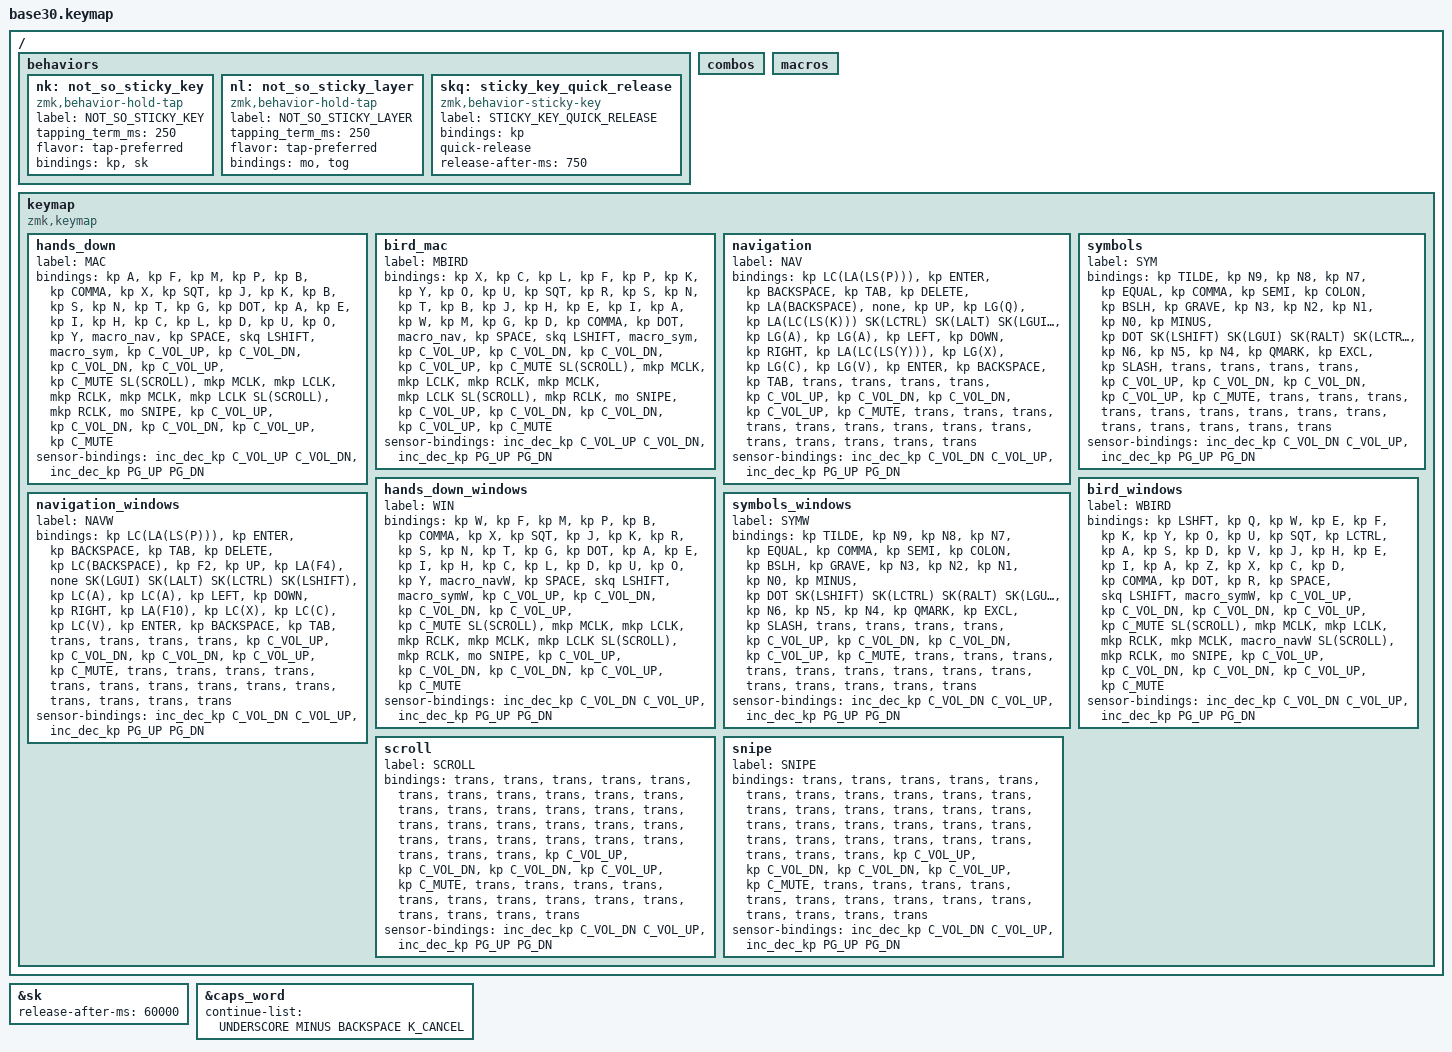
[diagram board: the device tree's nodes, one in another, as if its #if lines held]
/*
 * Copyright (c) 2020 The ZMK Contributors
 *
 * SPDX-License-Identifier: MIT
 */

#include <behaviors.dtsi>
#include <dt-bindings/zmk/keys.h>
#include <dt-bindings/zmk/bt.h>
#include <dt-bindings/zmk/outputs.h>

#define MAC 0
#define MBIRD 1
#define NAV 2
#define SYM 3
#define WIN 4
#define WBIRD 5
#define NAVW 6
#define SYMW 7
#ifdef GHAZAL
  #define SCROLL 8
  #define SNIPE 9
#endif

#define SK(KEY) &nk KEY KEY

#ifdef GHAZAL
  #define SL(LAYER) &nl LAYER LAYER
#endif

&sk {
  release-after-ms = <60000>;
};

&caps_word {
  continue-list = <UNDERSCORE MINUS BACKSPACE K_CANCEL>;
};


/*                KEY POSITIONS

  ╭────────────────────╮ ╭────────────────────╮
  │  0   1   2   3   4 │ │  5   6   7   8   9 │
  │ 10  11  12  13  14 │ │ 15  16  17  18  19 │
  │     20  21  22     │ │     23  24  25     │
  ╰───────────╮ 26  27 │ │ 28  29 ╭───────────╯
              ╰────────╯ ╰────────╯            */

/ {

  behaviors {

    // Sticky key on tap, normal key on hold
    // Useful for modifier-clicking without the modifier remaining active
    nk: not_so_sticky_key {
        compatible = "zmk,behavior-hold-tap";
        label = "NOT_SO_STICKY_KEY";
        #binding-cells = <2>;
        tapping_term_ms = <250>;
        flavor = "tap-preferred";
        bindings = <&kp>, <&sk>;
    };

#ifdef GHAZAL
    // Toggle layer on tap, normal layer on hold
    // Useful for scroll toggling without the scroll remaining active unless held
    nl: not_so_sticky_layer {
        compatible = "zmk,behavior-hold-tap";
        label = "NOT_SO_STICKY_LAYER";
        #binding-cells = <2>;
        tapping_term_ms = <250>;
        flavor = "tap-preferred";
        bindings = <&mo>, <&tog>;
    };
#endif

    skq: sticky_key_quick_release {
      compatible = "zmk,behavior-sticky-key";
      label = "STICKY_KEY_QUICK_RELEASE";
      #binding-cells = <1>;
      bindings = <&kp>;
      quick-release;
      release-after-ms = <750>;
    };

  };

  combos {
        #include "combos30.dtsi"
    };
  macros {
        #include "macros.dtsi"
#include <dt-bindings/zmk/mouse.h>
    };

 
        keymap {
                compatible = "zmk,keymap";
 
        hands_down {
            label = "MAC";
            bindings = <
// ╭─────────────┬─────────────┬─────────────┬─────────────┬─────────────╮   ╭─────────────┬─────────────┬─────────────┬─────────────┬─────────────╮
     &kp A         &kp F         &kp M         &kp P         &kp B             &kp COMMA     &kp X         &kp SQT       &kp J         &kp K
     &kp B         &kp S         &kp N         &kp T         &kp G             &kp DOT       &kp A         &kp E         &kp I         &kp H
                   &kp C         &kp L         &kp D                                         &kp U         &kp O         &kp Y
//               ╰─────────────┴─────────────┼─────────────┤                               ├─────────────┼─────────────┴─────────────╯
                                               &macro_nav   &kp SPACE          &skq LSHIFT    &macro_sym
//                                           ╰─────────────┴─────────────╯   ╰─────────────┴─────────────╯

            #ifdef WASFOORA
                  // up          left         down         right        middle
                   &kp C_VOL_UP  &kp C_VOL_DN &kp C_VOL_DN &kp C_VOL_UP &kp C_MUTE
            #endif

            #ifdef GHAZAL
              SL(SCROLL) 
              &mkp MCLK &mkp LCLK &mkp RCLK
              &mkp MCLK &mkp LCLK SL(SCROLL) &mkp RCLK &mo SNIPE    &kp C_VOL_UP  &kp C_VOL_DN &kp C_VOL_DN &kp C_VOL_UP &kp C_MUTE
            #endif

            >;
            #ifdef ENCODERS
              sensor-bindings = <&inc_dec_kp C_VOL_UP C_VOL_DN &inc_dec_kp PG_UP PG_DN>;
            #endif
        };

        bird_mac {
            label = "MBIRD";
            bindings = <
// ╭─────────────┬─────────────┬─────────────┬─────────────┬─────────────╮   ╭─────────────┬─────────────┬─────────────┬─────────────┬─────────────╮
     &kp X         &kp C         &kp L         &kp F         &kp P             &kp K         &kp Y         &kp O         &kp U         &kp SQT
     &kp R         &kp S         &kp N         &kp T         &kp B             &kp J         &kp H         &kp E         &kp I         &kp A
                   &kp W         &kp M         &kp G                                         &kp D         &kp COMMA     &kp DOT
//               ╰─────────────┴─────────────┼─────────────┤                               ├─────────────┼─────────────┴─────────────╯
                                               &macro_nav   &kp SPACE          &skq LSHIFT    &macro_sym
//                                           ╰─────────────┴─────────────╯   ╰─────────────┴─────────────╯

            #ifdef WASFOORA
                  // up          left         down         right        middle
                   &kp C_VOL_UP  &kp C_VOL_DN &kp C_VOL_DN &kp C_VOL_UP &kp C_MUTE
            #endif

            #ifdef GHAZAL
              SL(SCROLL) 
              &mkp MCLK &mkp LCLK &mkp RCLK
              &mkp MCLK &mkp LCLK SL(SCROLL) &mkp RCLK &mo SNIPE    &kp C_VOL_UP  &kp C_VOL_DN &kp C_VOL_DN &kp C_VOL_UP &kp C_MUTE
            #endif

            >;
            #ifdef ENCODERS
              sensor-bindings = <&inc_dec_kp C_VOL_UP C_VOL_DN &inc_dec_kp PG_UP PG_DN>;
            #endif
        };

        navigation {
            label = "NAV";
            bindings = <
// ╭─────────────┬─────────────┬─────────────┬─────────────┬─────────────╮   ╭─────────────┬─────────────┬─────────────┬─────────────┬─────────────╮
  &kp LC(LA(LS(P)))    &kp ENTER     &kp BACKSPACE  &kp TAB     &kp DELETE      &kp LA(BACKSPACE) &none         &kp UP        &kp LG(Q)  &kp LA(LC(LS(K)))
     SK(LCTRL)         SK(LALT)      SK(LGUI)       SK(LSHIFT)  &kp LG(A)       &kp LG(A)         &kp LEFT      &kp DOWN      &kp RIGHT  &kp LA(LC(LS(Y)))
                       &kp LG(X)     &kp LG(C)      &kp LG(V)                                     &kp ENTER     &kp BACKSPACE &kp TAB
//               ╰─────────────┴─────────────┼─────────────┤                               ├─────────────┼─────────────┴─────────────╯
                                                &trans        &trans            &trans       &trans
//                                           ╰─────────────┴─────────────╯   ╰─────────────┴─────────────╯

            #ifdef WASFOORA
                  // up          left         down         right        middle
                   &kp C_VOL_UP  &kp C_VOL_DN &kp C_VOL_DN &kp C_VOL_UP &kp C_MUTE
            #endif

            #ifdef GHAZAL
              &trans 
              &trans &trans &trans
              &trans &trans &trans &trans &trans       &trans &trans &trans &trans &trans
            #endif

            >;
            #ifdef ENCODERS
              sensor-bindings = <&inc_dec_kp C_VOL_DN C_VOL_UP &inc_dec_kp PG_UP PG_DN>;
            #endif
        };

        symbols {
            label = "SYM";
            bindings = <
// ╭─────────────┬─────────────┬─────────────┬─────────────┬─────────────╮   ╭─────────────┬─────────────┬─────────────┬─────────────┬─────────────╮
     &kp TILDE     &kp N9       &kp N8         &kp N7         &kp EQUAL         &kp COMMA    &kp SEMI      &kp COLON    &kp BSLH      &kp GRAVE
     &kp N3        &kp N2       &kp N1         &kp N0         &kp MINUS         &kp DOT      SK(LSHIFT)    SK(LGUI)     SK(RALT)      SK(LCTRL)
                   &kp N6       &kp N5         &kp N4                                        &kp QMARK     &kp EXCL     &kp SLASH
//               ╰─────────────┴─────────────┼─────────────┤                               ├─────────────┼─────────────┴─────────────╯
                                               &trans         &trans            &trans        &trans
//                                           ╰─────────────┴─────────────╯   ╰─────────────┴─────────────╯

            #ifdef WASFOORA
                  // up          left         down         right        middle
                   &kp C_VOL_UP  &kp C_VOL_DN &kp C_VOL_DN &kp C_VOL_UP &kp C_MUTE
            #endif

            #ifdef GHAZAL
              &trans 
              &trans &trans &trans
              &trans &trans &trans &trans &trans       &trans &trans &trans &trans &trans
            #endif

            >;
            #ifdef ENCODERS
              sensor-bindings = <&inc_dec_kp C_VOL_DN C_VOL_UP &inc_dec_kp PG_UP PG_DN>;
            #endif
        };

        hands_down_windows {
            label = "WIN";
            bindings = <
// ╭─────────────┬─────────────┬─────────────┬─────────────┬─────────────╮   ╭─────────────┬─────────────┬─────────────┬─────────────┬─────────────╮
     &kp W         &kp F         &kp M         &kp P         &kp B             &kp COMMA     &kp X         &kp SQT       &kp J         &kp K
     &kp R         &kp S         &kp N         &kp T         &kp G             &kp DOT       &kp A         &kp E         &kp I         &kp H
                   &kp C         &kp L         &kp D                                         &kp U         &kp O         &kp Y
//               ╰─────────────┴─────────────┼─────────────┤                               ├─────────────┼─────────────┴─────────────╯
                                               &macro_navW  &kp SPACE          &skq LSHIFT   &macro_symW
//                                           ╰─────────────┴─────────────╯   ╰─────────────┴─────────────╯

            #ifdef WASFOORA
                  // up          left         down         right        middle
                   &kp C_VOL_UP  &kp C_VOL_DN &kp C_VOL_DN &kp C_VOL_UP &kp C_MUTE
            #endif

            #ifdef GHAZAL
              SL(SCROLL) 
              &mkp MCLK &mkp LCLK &mkp RCLK
              &mkp MCLK &mkp LCLK SL(SCROLL) &mkp RCLK &mo SNIPE    &kp C_VOL_UP  &kp C_VOL_DN &kp C_VOL_DN &kp C_VOL_UP &kp C_MUTE
            #endif

            >;
            #ifdef ENCODERS
              sensor-bindings = <&inc_dec_kp C_VOL_DN C_VOL_UP &inc_dec_kp PG_UP PG_DN>;
            #endif
        };


        bird_windows {
            label = "WBIRD";
            bindings = <
// ╭─────────────┬─────────────┬─────────────┬─────────────┬─────────────╮   ╭─────────────┬─────────────┬─────────────┬─────────────┬─────────────╮
     &kp LSHFT     &kp Q         &kp W         &kp E         &kp F             &kp K         &kp Y         &kp O         &kp U         &kp SQT
     &kp LCTRL     &kp A         &kp S         &kp D         &kp V             &kp J         &kp H         &kp E         &kp I         &kp A
                   &kp Z         &kp X         &kp C                                         &kp D         &kp COMMA     &kp DOT
//               ╰─────────────┴─────────────┼─────────────┤                               ├─────────────┼─────────────┴─────────────╯
                                               &kp R  &kp SPACE          &skq LSHIFT   &macro_symW
//                                           ╰─────────────┴─────────────╯   ╰─────────────┴─────────────╯

            #ifdef WASFOORA
                  // up          left         down         right        middle
                   &kp C_VOL_UP  &kp C_VOL_DN &kp C_VOL_DN &kp C_VOL_UP &kp C_MUTE
            #endif

            #ifdef GHAZAL
              SL(SCROLL) 
              &mkp MCLK &mkp LCLK &mkp RCLK
              &mkp MCLK &macro_navW SL(SCROLL) &mkp RCLK &mo SNIPE    &kp C_VOL_UP  &kp C_VOL_DN &kp C_VOL_DN &kp C_VOL_UP &kp C_MUTE
            #endif

            >;
            #ifdef ENCODERS
              sensor-bindings = <&inc_dec_kp C_VOL_DN C_VOL_UP &inc_dec_kp PG_UP PG_DN>;
            #endif
        };
        
        navigation_windows {
            label = "NAVW";
            bindings = <
// ╭─────────────┬─────────────┬─────────────┬─────────────┬─────────────╮   ╭─────────────┬─────────────┬─────────────┬─────────────┬─────────────╮
&kp LC(LA(LS(P)))  &kp ENTER     &kp BACKSPACE  &kp TAB      &kp DELETE        &kp LC(BACKSPACE)  &kp F2        &kp UP        &kp LA(F4)    &none
     SK(LGUI)      SK(LALT)      SK(LCTRL)      SK(LSHIFT)   &kp LC(A)         &kp LC(A)          &kp LEFT      &kp DOWN      &kp RIGHT     &kp LA(F10)
                   &kp LC(X)     &kp LC(C)      &kp LC(V)                                         &kp ENTER     &kp BACKSPACE &kp TAB
//               ╰─────────────┴─────────────┼─────────────┤                               ├─────────────┼─────────────┴─────────────╯
                                                &trans          &trans         &trans        &trans
//                                           ╰─────────────┴─────────────╯   ╰─────────────┴─────────────╯

            #ifdef WASFOORA
                  // up          left         down         right        middle
                   &kp C_VOL_UP  &kp C_VOL_DN &kp C_VOL_DN &kp C_VOL_UP &kp C_MUTE
            #endif

            #ifdef GHAZAL
              &trans 
              &trans &trans &trans
              &trans &trans &trans &trans &trans       &trans &trans &trans &trans &trans
            #endif

            >;

            #ifdef ENCODERS
              sensor-bindings = <&inc_dec_kp C_VOL_DN C_VOL_UP &inc_dec_kp PG_UP PG_DN>;
            #endif
        };

        symbols_windows {
            label = "SYMW";
            bindings = <
// ╭─────────────┬─────────────┬─────────────┬─────────────┬─────────────╮   ╭─────────────┬─────────────┬─────────────┬─────────────┬─────────────╮
     &kp TILDE     &kp N9       &kp N8         &kp N7         &kp EQUAL         &kp COMMA    &kp SEMI      &kp COLON    &kp BSLH      &kp GRAVE
     &kp N3        &kp N2       &kp N1         &kp N0         &kp MINUS         &kp DOT      SK(LSHIFT)    SK(LCTRL)    SK(RALT)      SK(LGUI)
                   &kp N6       &kp N5         &kp N4                                        &kp QMARK     &kp EXCL     &kp SLASH
//               ╰─────────────┴─────────────┼─────────────┤                               ├─────────────┼─────────────┴─────────────╯
                                               &trans        &trans            &trans        &trans
//                                           ╰─────────────┴─────────────╯   ╰─────────────┴─────────────╯

            #ifdef WASFOORA
                  // up          left         down         right        middle
                   &kp C_VOL_UP  &kp C_VOL_DN &kp C_VOL_DN &kp C_VOL_UP &kp C_MUTE
            #endif

            #ifdef GHAZAL
              &trans 
              &trans &trans &trans
              &trans &trans &trans &trans &trans       &trans &trans &trans &trans &trans
            #endif
            
            >;

            #ifdef ENCODERS
              sensor-bindings = <&inc_dec_kp C_VOL_DN C_VOL_UP &inc_dec_kp PG_UP PG_DN>;
            #endif
        };

    #ifdef GHAZAL
        scroll {
            label = "SCROLL";
            bindings = <
// ╭─────────────┬─────────────┬─────────────┬─────────────┬─────────────╮   ╭─────────────┬─────────────┬─────────────┬─────────────┬─────────────╮
     &trans     &trans       &trans         &trans         &trans            &trans       &trans        &trans       &trans           &trans
     &trans        &trans       &trans         &trans         &trans            &trans       &trans        &trans       &trans        &trans
                   &trans       &trans         &trans         &trans            &trans       &trans        &trans       &trans
//               ╰─────────────┴─────────────┼─────────────┤                               ├─────────────┼─────────────┴─────────────╯
                                               &trans        &trans            &trans        &trans
//                                           ╰─────────────┴─────────────╯   ╰─────────────┴─────────────╯

            #ifdef WASFOORA
                  // up          left         down         right        middle
                   &kp C_VOL_UP  &kp C_VOL_DN &kp C_VOL_DN &kp C_VOL_UP &kp C_MUTE
            #endif

            #ifdef GHAZAL
              &trans
              &trans &trans &trans
              &trans &trans &trans &trans &trans       &trans &trans &trans &trans &trans
            #endif
            
            >;

            #ifdef ENCODERS
              sensor-bindings = <&inc_dec_kp C_VOL_DN C_VOL_UP &inc_dec_kp PG_UP PG_DN>;
            #endif
        };

        snipe {
            label = "SNIPE";
            bindings = <
// ╭─────────────┬─────────────┬─────────────┬─────────────┬─────────────╮   ╭─────────────┬─────────────┬─────────────┬─────────────┬─────────────╮
     &trans     &trans       &trans         &trans         &trans            &trans       &trans        &trans       &trans           &trans
     &trans        &trans       &trans         &trans         &trans            &trans       &trans        &trans       &trans        &trans
                   &trans       &trans         &trans         &trans            &trans       &trans        &trans       &trans
//               ╰─────────────┴─────────────┼─────────────┤                               ├─────────────┼─────────────┴─────────────╯
                                               &trans        &trans            &trans        &trans
//                                           ╰─────────────┴─────────────╯   ╰─────────────┴─────────────╯

            #ifdef WASFOORA
                  // up          left         down         right        middle
                   &kp C_VOL_UP  &kp C_VOL_DN &kp C_VOL_DN &kp C_VOL_UP &kp C_MUTE
            #endif

            #ifdef GHAZAL
              &trans
              &trans &trans &trans
              &trans &trans &trans &trans &trans       &trans &trans &trans &trans &trans
            #endif
            
            >;

            #ifdef ENCODERS
              sensor-bindings = <&inc_dec_kp C_VOL_DN C_VOL_UP &inc_dec_kp PG_UP PG_DN>;
            #endif
        };
    #endif
  };

};
